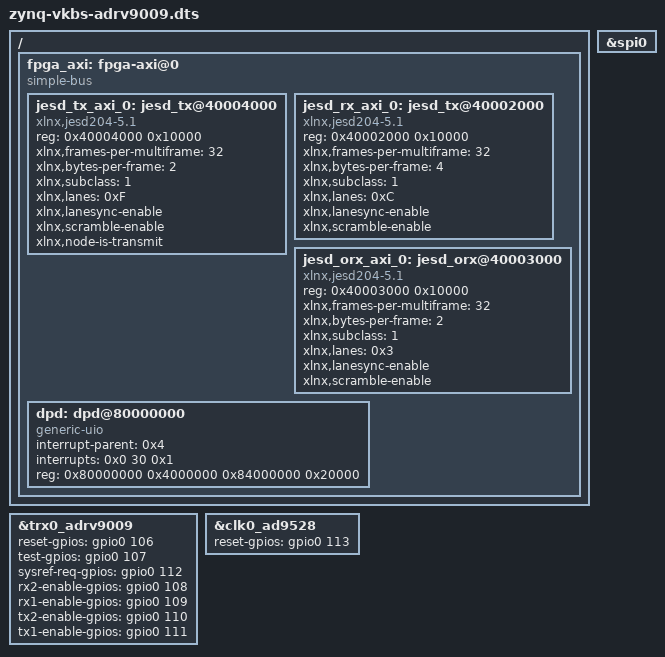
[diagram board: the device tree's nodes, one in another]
/dts-v1/;

/include/ "zynq-vkbs.dtsi"

/ {
	fpga_axi: fpga-axi@0 {
		compatible = "simple-bus";
		#address-cells = <0x1>;
		#size-cells = <0x1>;
		ranges;

	jesd_tx_axi_0: jesd_tx@40004000 {
		compatible = "xlnx,jesd204-5.1";
		reg = <0x40004000 0x10000>;
			xlnx,frames-per-multiframe = <32>;
			xlnx,bytes-per-frame = <2>;
			xlnx,subclass = <1>;
			xlnx,lanes = <0xF>;
			xlnx,lanesync-enable;
			xlnx,scramble-enable;
			xlnx,node-is-transmit;
	} ;

	jesd_rx_axi_0: jesd_tx@40002000 {
		compatible = "xlnx,jesd204-5.1";
		reg = <0x40002000 0x10000>;
			xlnx,frames-per-multiframe = <32>;
			xlnx,bytes-per-frame = <4>;
			xlnx,subclass = <1>;
			xlnx,lanes = <0xC>;
			xlnx,lanesync-enable;
			xlnx,scramble-enable;

	} ;

	jesd_orx_axi_0: jesd_orx@40003000 {
		compatible = "xlnx,jesd204-5.1";
		reg = <0x40003000 0x10000>;
			xlnx,frames-per-multiframe = <32>;
			xlnx,bytes-per-frame = <2>;
			xlnx,subclass = <1>;
			xlnx,lanes = <0x3>;
			xlnx,lanesync-enable;
			xlnx,scramble-enable;
	} ;

		dpd: dpd@80000000 {
			compatible = "generic-uio";
			interrupt-parent = <0x4>;
			interrupts = <0x0 30 0x1>;
			reg = <0x80000000 0x4000000 0x84000000 0x20000>;
		};
	};
};


&spi0 {
	status = "okay";
};

#define fmc_spi spi0

#include "adi-adrv9009.dtsi"

// adrv9009_dac_fifo_bypass_s 60
// ad9528_reset_b,       // 59
// ad9528_sysref_req,    // 58
// adrv9009_tx1_enable,    // 57
// adrv9009_tx2_enable,    // 56
// adrv9009_rx1_enable,    // 55
// adrv9009_rx2_enable,    // 54
// adrv9009_test,          // 53
// adrv9009_reset_b,       // 52
// adrv9009_gpint,         // 51
// adrv9009_gpio_00,       // 50
// adrv9009_gpio_01,       // 49
// adrv9009_gpio_02,       // 48
// adrv9009_gpio_03,       // 47
// adrv9009_gpio_04,       // 46
// adrv9009_gpio_05,       // 45
// adrv9009_gpio_06,       // 44
// adrv9009_gpio_07,       // 43
// adrv9009_gpio_15,       // 42
// adrv9009_gpio_08,       // 41
// adrv9009_gpio_09,       // 40
// adrv9009_gpio_10,       // 39
// adrv9009_gpio_11,       // 38
// adrv9009_gpio_12,       // 37
// adrv9009_gpio_14,       // 36
// adrv9009_gpio_13,       // 35
// adrv9009_gpio_17,       // 34
// adrv9009_gpio_16,       // 33
// adrv9009_gpio_18}));    // 32 + 54

&trx0_adrv9009 {
	reset-gpios = <&gpio0 106 0>;
	test-gpios = <&gpio0 107 0>;
	sysref-req-gpios = <&gpio0 112 0>;
	rx2-enable-gpios = <&gpio0 108 0>;
	rx1-enable-gpios = <&gpio0 109 0>;
	tx2-enable-gpios = <&gpio0 110 0>;
	tx1-enable-gpios = <&gpio0 111 0>;
};

&clk0_ad9528 {
	reset-gpios = <&gpio0 113 0>;
};


